# ATSAMHA1G17AB register map
Vendor: Microchip Technology; Series: SAMHA1; File version: 0
CPU: CM0+ r0p0, selectable endian, no MPU, no FPU, VTOR, 2 interrupt priority bits
Registers are 32-bit, read-write, reset 0x0 unless marked. A register's access mark holds for its fields unless they carry their own. Offsets are from the block's base; [hi:lo] are bit positions; lines under a group give offsets from that group; {n}, {i} and the like mark numbered series; 'fields as' and 'values as' point back to an identical list.

## PORT — Port Module
Base 0x41004400; register names take the prefix PORT_
Same registers: PORT_IOBUS 0x60000000 (register names take the prefix PORT_IOBUS_)
{0x0+0x80*i} GROUP[{i}] (i=0..1) group
  0x00 DIR — Data Direction
    [31:0] DIR — Port Data Direction
  0x04 DIRCLR — Data Direction Clear
    [31:0] DIRCLR — Port Data Direction Clear
  0x08 DIRSET — Data Direction Set
    [31:0] DIRSET — Port Data Direction Set
  0x0C DIRTGL — Data Direction Toggle
    [31:0] DIRTGL — Port Data Direction Toggle
  0x10 OUT — Data Output Value
    [31:0] OUT — Port Data Output Value
  0x14 OUTCLR — Data Output Value Clear
    [31:0] OUTCLR — Port Data Output Value Clear
  0x18 OUTSET — Data Output Value Set
    [31:0] OUTSET — Port Data Output Value Set
  0x1C OUTTGL — Data Output Value Toggle
    [31:0] OUTTGL — Port Data Output Value Toggle
  0x20 IN ro — Data Input Value
    [31:0] IN — Port Data Input Value
  0x24 CTRL — Control
    [31:0] SAMPLING — Input Sampling Mode
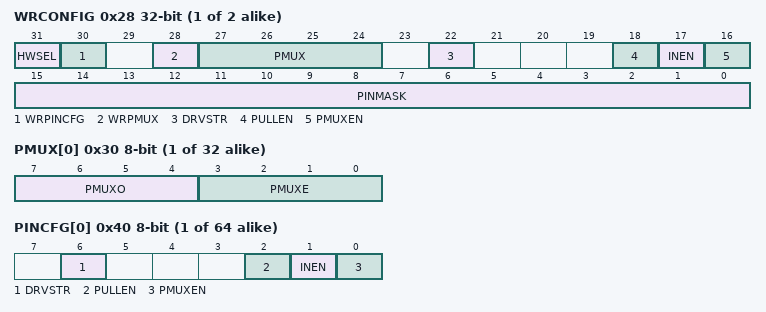
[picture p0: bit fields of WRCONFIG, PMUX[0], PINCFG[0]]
  0x28 WRCONFIG wo — Write Configuration
    [31] HWSEL — Half-Word Select
    [30] WRPINCFG — Write PINCFG
    [28] WRPMUX — Write PMUX
    [27:24] PMUX — Peripheral Multiplexing
    [22] DRVSTR — Output Driver Strength Selection
    [18] PULLEN — Pull Enable
    [17] INEN — Input Enable
    [16] PMUXEN — Peripheral Multiplexer Enable
    [15:0] PINMASK — Pin Mask for Multiple Pin Configuration
  {0x30+j} PMUX[{j}] (j=0..15) 8-bit — Peripheral Multiplexing n
    [7:4] PMUXO — Peripheral Multiplexing Odd
      0=A (Peripheral function A selected); 1=B (Peripheral function B selected); 2=C (Peripheral function C selected); 3=D (Peripheral function D selected); 4=E (Peripheral function E selected); 5=F (Peripheral function F selected); 6=G (Peripheral function G selected); 7=H (Peripheral function H selected)
    [3:0] PMUXE — Peripheral Multiplexing Even
      values as PMUXO
  {0x40+j} PINCFG[{j}] (j=0..31) 8-bit — Pin Configuration n
    [6] DRVSTR — Output Driver Strength Selection
    [2] PULLEN — Pull Enable
    [1] INEN — Input Enable
    [0] PMUXEN — Peripheral Multiplexer Enable

## PTC — Peripheral Touch Controller
Base 0x42004C00; register names take the prefix PTC_

## WDT — Watchdog Timer
Base 0x40001000; register names take the prefix WDT_
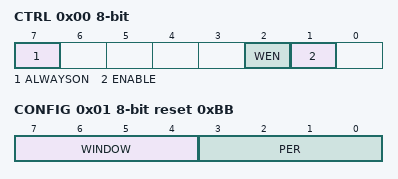
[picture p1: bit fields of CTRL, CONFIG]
0x00 CTRL 8-bit — Control
  [7] ALWAYSON
  [2] WEN — Watchdog Timer Window Mode Enable
  [1] ENABLE
0x01 CONFIG 8-bit reset 0xBB — Configuration
  [7:4] WINDOW — Window Mode Time-Out Period
    0=8 clock cycles; 1=16 clock cycles; 2=32 clock cycles; 3=64 clock cycles; 4=128 clock cycles; 5=256 clock cycles; 6=512 clock cycles; 7=1K (1024 clock cycles); 8=2K (2048 clock cycles); 9=4K (4096 clock cycles); 10=8K (8192 clock cycles); 11=16K (16384 clock cycles)
  [3:0] PER — Time-Out Period
    values as WINDOW
0x02 EWCTRL 8-bit reset 0xB — Early Warning Interrupt Control
  [3:0] EWOFFSET — Early Warning Interrupt Time Offset
    values as CONFIG.WINDOW
0x04 INTENCLR 8-bit — Interrupt Enable Clear
  [0] EW — Early Warning Interrupt Enable
0x05 INTENSET 8-bit — Interrupt Enable Set
  [0] EW — Early Warning Interrupt Enable
0x06 INTFLAG 8-bit — Interrupt Flag Status and Clear
  [0] EW — Early Warning
0x07 STATUS 8-bit ro
  [7] SYNCBUSY — Synchronization Busy
0x08 CLEAR 8-bit wo
  [7:0] CLEAR — Watchdog Clear
    165=KEY (Clear Key)

## NVIC — Nested Vectored Interrupt Controller
Base 0xE000E100; register names take the prefix NVIC_
0x00 ISER — Interrupt Set Enable Register
  [29:0] SETENA — Interrupt set enable bits
0x80 ICER — Interrupt Clear Enable Register
  [29:0] CLRENA — Interrupt clear-enable bits
0x100 ISPR — Interrupt Set Pending Register
  [29:0] SETPEND — Interrupt set-pending bits
0x180 ICPR — Interrupt Clear Pending Register
  [29:0] CLRPEND — Interrupt clear-pending bits
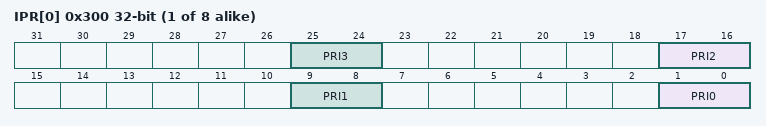
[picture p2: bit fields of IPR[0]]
{0x300+4i} IPR[{i}] (i=0..7) — Interrupt Priority Register n
  [8n+1:8n] PRI{n} (n=0..3) — Priority of interrupt n

## Notices in the file
Copyright (c) 2017 Microchip Technology Inc.
SPDX-License-Identifier: Apache-2.0
Licensed under the Apache License, Version 2.0 (the "License");
you may not use this file except in compliance with the License.
You may obtain a copy of the License at
http://www.apache.org/licenses/LICENSE-2.0
Unless required by applicable law or agreed to in writing, software
distributed under the License is distributed on an "AS IS" BASIS,
WITHOUT WARRANTIES OR CONDITIONS OF ANY KIND, either express or implied.
See the License for the specific language governing permissions and
limitations under the License.
